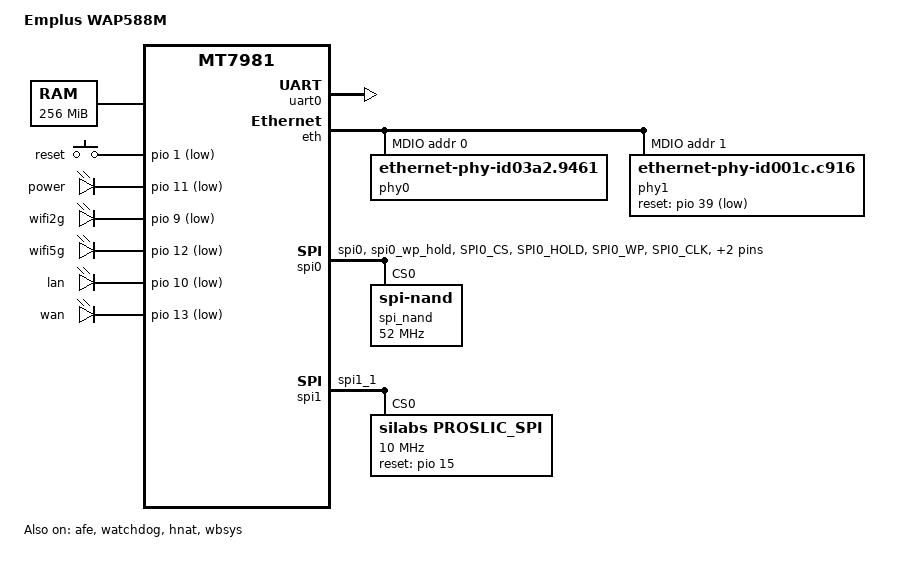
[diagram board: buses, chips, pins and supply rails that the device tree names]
/dts-v1/;
#include "mt7981.dtsi"
/ {
	model = "Emplus WAP588M";
	compatible = "emplus,wap588m";
	chosen {
		bootargs = "console=ttyS0,115200n1 loglevel=8  \
				earlycon=uart8250,mmio32,0x11002000";
	};

	memory {
		reg = <0 0x40000000 0 0x10000000>;
	};

	gpio-keys {
		compatible = "gpio-keys";

		reset {
			label = "reset";
			linux,code = <KEY_RESTART>;
			gpios = <&pio 1 GPIO_ACTIVE_LOW>;
				};
	};

	leds {
		compatible = "gpio-leds";
		power {
			label = "power";
			gpios = <&pio 11 GPIO_ACTIVE_LOW>;
			linux,default-trigger = "timer";
			default-state = "on";

		};
		wifi2g {
			label = "wifi2g";
			gpios = <&pio 9 GPIO_ACTIVE_LOW>;
			linux,default-trigger = "ra0";
		};
		wifi5g {
			label = "wifi5g";
			gpios = <&pio 12 GPIO_ACTIVE_LOW>;
			linux,default-trigger = "rax0";
		};
		lan {
			label = "lan";
			gpios = <&pio 10 GPIO_ACTIVE_LOW>;
			linux,default-trigger = "eth0";
		};
		wan {
			label = "wan";
			gpios = <&pio 13 GPIO_ACTIVE_LOW>;
			linux,default-trigger = "eth1";
		};
	};

	nmbm_spim_nand {
		compatible = "generic,nmbm";

		#address-cells = <1>;
		#size-cells = <1>;

		lower-mtd-device = <&spi_nand>;
		forced-create;

		partitions {
			compatible = "fixed-partitions";
			#address-cells = <1>;
			#size-cells = <1>;

			partition@0 {
				label = "BL2";
				reg = <0x00000 0x0100000>;
				read-only;
			};

			partition@100000 {
				label = "u-boot-env";
				reg = <0x0100000 0x0080000>;
			};

			factory: partition@180000 {
				label = "Factory";
				reg = <0x180000 0x0200000>;
			};

			partition@380000 {
				label = "FIP";
				reg = <0x380000 0x0200000>;
			};

			partition@580000 {
				label = "ubi"; //110MB
				reg = <0x580000 0x3700000>;
			};

			partition@3C80000 {
				label = "ubi_1"; //110MB
				reg = <0x3C80000 0x3700000>;
			};

			partition@7380000 {
				label = "cert"; //384KB
				reg = <0x7380000 0x0060000>;
			};

			partition@73E0000 {
				label = "userconfig"; //640KB
				reg = <0x73E0000 0x00a0000>;
			};

			partition@7480000 {
				label = "crashdump"; //384KB
				reg = <0x7480000 0x0060000>;
			};
		};
	};

	sound_wm8960 {
		compatible = "mediatek,mt79xx-wm8960-machine";
		mediatek,platform = <&afe>;
		audio-routing = "Headphone", "HP_L",
				"Headphone", "HP_R",
				"LINPUT1", "AMIC",
				"RINPUT1", "AMIC";
		mediatek,audio-codec = <&wm8960>;
		status = "disabled";
	};

	sound_si3218x {
		compatible = "mediatek,mt79xx-si3218x-machine";
		mediatek,platform = <&afe>;
		mediatek,ext-codec = <&proslic_spi>;
		status = "disabled";
	};
};

&afe {
	pinctrl-names = "default";
	pinctrl-0 = <&pcm_pins>;
	status = "okay";
};

&i2c0 {
	pinctrl-names = "default";
	pinctrl-0 = <&i2c_pins>;
	status = "disabled";

	wm8960: wm8960@1a {
		compatible = "wlf,wm8960";
		reg = <0x1a>;
	};
};

&uart0 {
	status = "okay";
};

&watchdog {
	status = "okay";
};

&eth {
        status = "okay";

        gmac0: mac@0 {
                compatible = "mediatek,eth-mac";
                reg = <0>;
                phy-mode = "sgmii";
                phy-handle = <&phy1>;
        };

	gmac1: mac@1 {
		compatible = "mediatek,eth-mac";
		reg = <1>;
		phy-mode = "gmii";
		phy-handle = <&phy0>;
	};

        mdio: mdio-bus {
                #address-cells = <1>;
                #size-cells = <0>;

		// MT7981 internal PHY
		phy0: ethernet-phy@0 {
			compatible = "ethernet-phy-id03a2.9461";
			reg = <0>;
			phy-mode = "gmii";
			nvmem-cells = <&phy_calibration>;
			nvmem-cell-names = "phy-cal-data";
		};


		// RTL8211FS PHY
		phy1: ethernet-phy@1 {
			compatible = "ethernet-phy-id001c.c916";
			reg = <1>;
			reset-gpios = <&pio 39 GPIO_ACTIVE_LOW>;
			reset-assert-us = <120000>;
			reset-deassert-us = <120000>;
			phy-mode = "sgmii";
		};
    };
};

&hnat {
	mtketh-wan = "eth1";
	mtketh-lan = "eth0";
	mtketh-max-gmac = <2>;
	status = "okay";
};

&spi0 {
	pinctrl-names = "default";
	pinctrl-0 = <&spi0_flash_pins>;
	status = "okay";
	spi_nand: spi_nand@0 {
		#address-cells = <1>;
		#size-cells = <1>;
		compatible = "spi-nand";
		reg = <0>;
		spi-max-frequency = <52000000>;
		spi-tx-bus-width = <4>;
		spi-rx-bus-width = <4>;
	};
};

&spi1 {
	pinctrl-names = "default";
	pinctrl-0 = <&spic_pins>;
	status = "okay";

	proslic_spi: proslic_spi@0 {
		compatible = "silabs,proslic_spi";
		reg = <0>;
		spi-max-frequency = <10000000>;
		spi-cpha = <1>;
		spi-cpol = <1>;
		channel_count = <1>;
		debug_level = <4>;       /* 1 = TRC, 2 = DBG, 4 = ERR */
		reset_gpio = <&pio 15 0>;
		ig,enable-spi = <1>;     /* 1: Enable, 0: Disable */
	};
};

&wbsys {
	mediatek,mtd-eeprom = <&factory 0x0000>;
	status = "okay";
	pinctrl-names = "dbdc";
	pinctrl-0 = <&wf_dbdc_pins>;
};

&pio {

	i2c_pins: i2c-pins-g0 {
                mux {
                        function = "i2c";
                        groups = "i2c0_0";
                };
        };

        pcm_pins: pcm-pins-g0 {
                mux {
                        function = "pcm";
                        groups = "pcm";
                };
        };

        pwm0_pin: pwm0-pin-g0 {
                mux {
                        function = "pwm";
                        groups = "pwm0_0";
                };
        };

        pwm1_pin: pwm1-pin-g0 {
                mux {
                        function = "pwm";
                        groups = "pwm1_0";
                };
        };

        pwm2_pin: pwm2-pin {
                mux {
                        function = "pwm";
                        groups = "pwm2";
                };
        };

	spi0_flash_pins: spi0-pins {
		mux {
			function = "spi";
			groups = "spi0", "spi0_wp_hold";
		};

		conf-pu {
			pins = "SPI0_CS", "SPI0_HOLD", "SPI0_WP";
			drive-strength = <MTK_DRIVE_8mA>;
			bias-pull-up = <MTK_PUPD_SET_R1R0_11>;
		};

		conf-pd {
			pins = "SPI0_CLK", "SPI0_MOSI", "SPI0_MISO";
			drive-strength = <MTK_DRIVE_8mA>;
			bias-pull-down = <MTK_PUPD_SET_R1R0_11>;
		};
	};

	spic_pins: spi1-pins {
		mux {
			function = "spi";
			groups = "spi1_1";
		};
	};

	uart1_pins: uart1-pins-g1 {
                mux {
                        function = "uart";
                        groups = "uart1_1";
                };
        };

	uart2_pins: uart2-pins-g1 {
		mux {
                        function = "uart";
                        groups = "uart2_1";
                };
        };
	wf_dbdc_pins: wf_dbdc-pins {
		mux {
			function = "eth";
			groups = "wf0_mode1";
		};
		conf {
			pins = "WF_HB1", "WF_HB2", "WF_HB3", "WF_HB4",
			       "WF_HB0", "WF_HB0_B", "WF_HB5", "WF_HB6",
			       "WF_HB7", "WF_HB8", "WF_HB9", "WF_HB10",
			       "WF_TOP_CLK", "WF_TOP_DATA", "WF_XO_REQ",
			       "WF_CBA_RESETB", "WF_DIG_RESETB";
			drive-strength = <MTK_DRIVE_4mA>;
		};
	};
};

&xhci {
	mediatek,u3p-dis-msk = <0x0>;
	phys = <&u2port0 PHY_TYPE_USB2>,
	       <&u3port0 PHY_TYPE_USB3>;
	status = "disabled";
};
